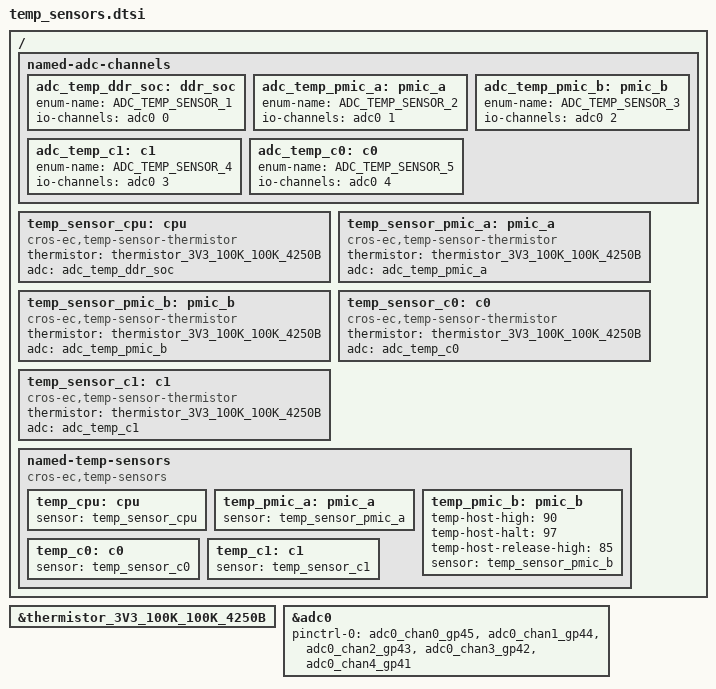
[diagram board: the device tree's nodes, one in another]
/* Copyright 2026 The ChromiumOS Authors
 * Use of this source code is governed by a BSD-style license that can be
 * found in the LICENSE file.
 */

#include <cros/thermistor/thermistor.dtsi>

/ {
	named-adc-channels {

		adc_temp_ddr_soc: ddr_soc {
			enum-name = "ADC_TEMP_SENSOR_1";
			io-channels = <&adc0 0>;
		};
		adc_temp_pmic_a: pmic_a {
			enum-name = "ADC_TEMP_SENSOR_2";
			io-channels = <&adc0 1>;
		};
		adc_temp_pmic_b: pmic_b {
			enum-name = "ADC_TEMP_SENSOR_3";
			io-channels = <&adc0 2>;
		};
		adc_temp_c1: c1 {
			enum-name = "ADC_TEMP_SENSOR_4";
			io-channels = <&adc0 3>;
		};
		adc_temp_c0: c0 {
			enum-name = "ADC_TEMP_SENSOR_5";
			io-channels = <&adc0 4>;
		};
	};

	temp_sensor_cpu: cpu {
		compatible = "cros-ec,temp-sensor-thermistor";
		thermistor = <&thermistor_3V3_100K_100K_4250B>;
		adc = <&adc_temp_ddr_soc>;
	};
	temp_sensor_pmic_a: pmic_a {
		compatible = "cros-ec,temp-sensor-thermistor";
		thermistor = <&thermistor_3V3_100K_100K_4250B>;
		adc = <&adc_temp_pmic_a>;
	};
	temp_sensor_pmic_b: pmic_b {
		compatible = "cros-ec,temp-sensor-thermistor";
		thermistor = <&thermistor_3V3_100K_100K_4250B>;
		adc = <&adc_temp_pmic_b>;
	};
	temp_sensor_c0: c0 {
		compatible = "cros-ec,temp-sensor-thermistor";
		thermistor = <&thermistor_3V3_100K_100K_4250B>;
		adc = <&adc_temp_c0>;
	};
	temp_sensor_c1: c1 {
		compatible = "cros-ec,temp-sensor-thermistor";
		thermistor = <&thermistor_3V3_100K_100K_4250B>;
		adc = <&adc_temp_c1>;
	};

	named-temp-sensors {
		compatible = "cros-ec,temp-sensors";
		temp_cpu: cpu {
			sensor = <&temp_sensor_cpu>;
		};
		temp_pmic_a: pmic_a {
			sensor = <&temp_sensor_pmic_a>;
		};
		temp_pmic_b: pmic_b {
			temp-host-high = <90>;
			temp-host-halt = <97>;
			temp-host-release-high = <85>;
			sensor = <&temp_sensor_pmic_b>;
		};
		temp_c0: c0 {
			sensor = <&temp_sensor_c0>;
		};
		temp_c1: c1 {
			sensor = <&temp_sensor_c1>;
		};
	};
};

&thermistor_3V3_100K_100K_4250B {
	status = "okay";
};

&adc0 {
	pinctrl-0 = <&adc0_chan0_gp45
		&adc0_chan1_gp44
		&adc0_chan2_gp43
		&adc0_chan3_gp42
		&adc0_chan4_gp41>;
	pinctrl-names = "default";
};
